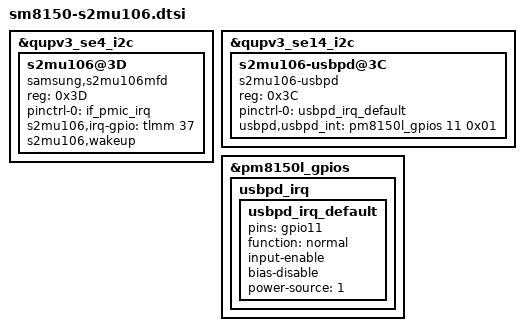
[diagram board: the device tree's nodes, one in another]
/* Copyright (c) 2012, The Linux Foundation. All rights reserved.
 *
 * This program is free software; you can redistribute it and/or modify
 * it under the terms of the GNU General Public License version 2 and
 * only version 2 as published by the Free Software Foundation.
 *
 * This program is distributed in the hope that it will be useful,
 * but WITHOUT ANY WARRANTY; without even the implied warranty of
 * MERCHANTABILITY or FITNESS FOR A PARTICULAR PURPOSE.  See the
 * GNU General Public License for more details.
 */


&qupv3_se4_i2c {
	status = "ok";
	s2mu106@3D {
		status = "okay";
		compatible = "samsung,s2mu106mfd";
		reg = <0x3D>;
		pinctrl-names = "default";
		pinctrl-0 = <&if_pmic_irq>;
		s2mu106,irq-gpio = <&tlmm 37 0>;
		s2mu106,wakeup;
	};
};

&qupv3_se14_i2c {
	status = "ok";
	s2mu106-usbpd@3C {
		compatible = "s2mu106-usbpd";
		reg = <0x3C>;
		pinctrl-names = "default";
		pinctrl-0     = <&usbpd_irq_default>;
            	usbpd,usbpd_int = <&pm8150l_gpios 11 0x01>;
    };
};

&pm8150l_gpios {
    usbpd_irq {
        usbpd_irq_default: usbpd_irq_default {
            pins = "gpio11";
            function = "normal";
            input-enable;
            bias-disable;
            power-source = <1>;
        };
    };
};
